AUTOSAR XML (schema 4-0-3)
standard types defined: UInt32, UInt8
package /AUTOSAR_Platform/DataConstrs
  range DC_UInt8: raw 0..255
package /PATAC/MSM/ComponentTypes
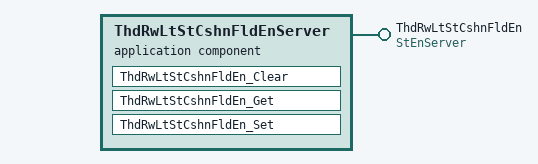
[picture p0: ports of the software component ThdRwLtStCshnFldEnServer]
  application sw component type ThdRwLtStCshnFldEnServer
    provide port ThdRwLtStCshnFldEn: provided-com-specs=[{operation=Clear, queue-length=1}, {operation=Get, queue-length=1}, {operation=Set, queue-length=1}], provided-interface=StEnServer
    behavior ThdRwLtStCshnFldEnServer_InternalBehavior
      operation invoked event OIT_ThdRwLtStCshnFldEn_Clear_ThdRwLtStCshnFldEn_Clear: start-on-event=ThdRwLtStCshnFldEn_Clear, operation=ThdRwLtStCshnFldEn.Clear
      operation invoked event OIT_ThdRwLtStCshnFldEn_Get_ThdRwLtStCshnFldEn_Get: start-on-event=ThdRwLtStCshnFldEn_Get, operation=ThdRwLtStCshnFldEn.Get
      operation invoked event OIT_ThdRwLtStCshnFldEn_Set_ThdRwLtStCshnFldEn_Set: start-on-event=ThdRwLtStCshnFldEn_Set, operation=ThdRwLtStCshnFldEn.Set
      runnable ThdRwLtStCshnFldEn_Clear
      runnable ThdRwLtStCshnFldEn_Get
      runnable ThdRwLtStCshnFldEn_Set
  swc implementation ThdRwLtStCshnFldEnServer_Implementation: behavior=ThdRwLtStCshnFldEnServer_InternalBehavior
    code-descriptors:
      code Default: artifact-descriptors=autosar-engineering-object={short-label=Default, category=SWSRC}
package /PATAC/MSM/ModeAdjust/PortInterface
  client server interface StEnServer
    operation Clear
      arg data: type=UInt8, direction=IN, server-argument-impl-policy=USE-ARGUMENT-TYPE
    operation Get
      arg data: type=UInt32, direction=OUT, server-argument-impl-policy=USE-ARGUMENT-TYPE
    operation Set
      arg data: type=UInt8, direction=IN, server-argument-impl-policy=USE-ARGUMENT-TYPE
